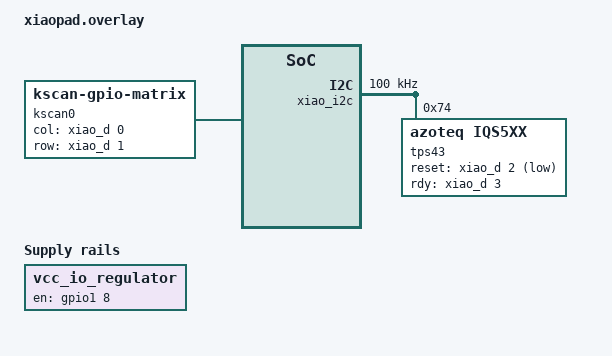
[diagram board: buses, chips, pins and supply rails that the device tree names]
#include <dt-bindings/zmk/matrix_transform.h>

/ {
    /* 1. Setup the input listener to capture trackpad data */
    tps43_input: tps43_input {
        compatible = "zmk,input-listener";
        device = <&tps43>;
    };

    /* 2. Create a virtual 1x1 keymatrix switch line to satisfy ZMK */
    chosen {
        zmk,kscan = &kscan0;
        zmk,matrix-transform = &default_transform;
    };

    default_transform: keymap_transform_0 {
        compatible = "zmk,matrix-transform";
        columns = <1>;
        rows = <1>;
        map = <
            RC(0,0)
        >;
    };
    
    kscan0: kscan {
        compatible = "zmk,kscan-gpio-matrix";
        wakeup-source;
        diode-direction = "col2row";
        col-gpios = <&xiao_d 0 GPIO_ACTIVE_HIGH>;
        row-gpios = <&xiao_d 1 (GPIO_ACTIVE_HIGH | GPIO_PULL_DOWN)>;
    };

    /* 3. Force the internal VCC_IO power gate high to power the 3.3V rail */
    vcc_io_regulator: regulator {
        compatible = "regulator-fixed";
        regulator-name = "vcc_io";
        enable-gpios = <&gpio1 8 GPIO_ACTIVE_HIGH>; // Powers P1.08 (Internal Power Switch)
        regulator-always-on;
        regulator-boot-on;
    };
};

&xiao_i2c  {
    status = "okay";
    clock-frequency = <I2C_BITRATE_STANDARD>;
    tps43: iqs5xx@74 {
        compatible = "azoteq,iqs5xx";
        status = "okay";
        reg = <0x74>;
        
        reset-gpios = <&xiao_d 2 GPIO_ACTIVE_LOW>;
        rdy-gpios = <&xiao_d 3 GPIO_ACTIVE_HIGH>;

        /* https://github.com/AYM1607/zmk-driver-azoteq-iqs5xx/blob/main/dts/bindings/input/azoteq%2Ciqs5xx-common.yaml */
        one-finger-tap;        
        press-and-hold;
        press-and-hold-time = <250>;
        two-finger-tap;
        scroll;
        natural-scroll-y;
        natural-scroll-x;
        bottom-beta = <5>;
        stationary-threshold = <5>;
        switch-xy;
    };
};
